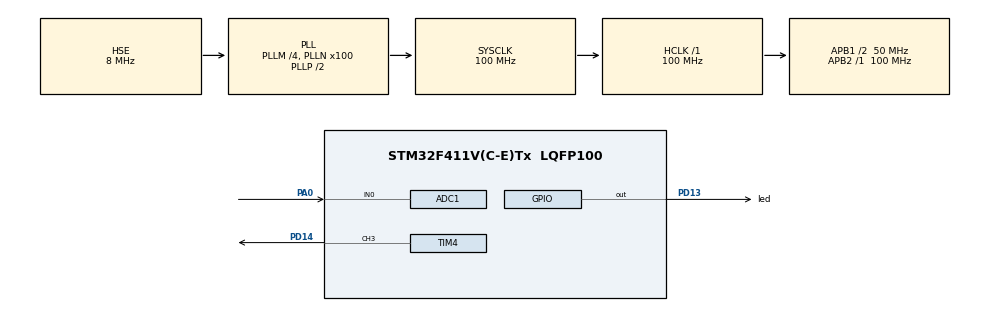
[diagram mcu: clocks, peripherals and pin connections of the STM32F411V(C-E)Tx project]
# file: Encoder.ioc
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ADC1.Channel-16\#ChannelRegularConversion=ADC_CHANNEL_0
ADC1.ClockPrescaler=ADC_CLOCK_SYNC_PCLK_DIV8
ADC1.ContinuousConvMode=ENABLE
ADC1.DMAContinuousRequests=ENABLE
ADC1.DataAlign=ADC_DATAALIGN_RIGHT
ADC1.DiscontinuousConvMode=DISABLE
ADC1.EOCSelection=ADC_EOC_SINGLE_CONV
ADC1.EnableAnalogWatchDog=false
ADC1.ExternalTrigConv=ADC_SOFTWARE_START
ADC1.ExternalTrigConvEdge=ADC_EXTERNALTRIGCONVEDGE_NONE
ADC1.InjNumberOfConversion=0
ADC1.NbrOfConversion=1
ADC1.NbrOfConversionFlag=1
ADC1.Rank-16\#ChannelRegularConversion=1
ADC1.Resolution=ADC_RESOLUTION_12B
ADC1.SamplingTime-16\#ChannelRegularConversion=ADC_SAMPLETIME_480CYCLES
ADC1.ScanConvMode=ENABLE
ADC1.master=1
Dma.ADC1.0.Direction=DMA_PERIPH_TO_MEMORY
Dma.ADC1.0.FIFOMode=DMA_FIFOMODE_DISABLE
Dma.ADC1.0.Instance=DMA2_Stream0
Dma.ADC1.0.MemDataAlignment=DMA_MDATAALIGN_HALFWORD
Dma.ADC1.0.MemInc=DMA_MINC_ENABLE
Dma.ADC1.0.Mode=DMA_CIRCULAR
Dma.ADC1.0.PeriphDataAlignment=DMA_PDATAALIGN_HALFWORD
Dma.ADC1.0.PeriphInc=DMA_PINC_DISABLE
Dma.ADC1.0.Priority=DMA_PRIORITY_LOW
Dma.Request0=ADC1
Dma.Request1=TIM4_CH3
Dma.TIM4_CH3.1.Direction=DMA_PERIPH_TO_MEMORY
Dma.TIM4_CH3.1.FIFOMode=DMA_FIFOMODE_DISABLE
Dma.TIM4_CH3.1.Instance=DMA1_Stream7
Dma.TIM4_CH3.1.MemDataAlignment=DMA_MDATAALIGN_HALFWORD
Dma.TIM4_CH3.1.MemInc=DMA_MINC_ENABLE
Dma.TIM4_CH3.1.Mode=DMA_CIRCULAR
Dma.TIM4_CH3.1.PeriphDataAlignment=DMA_PDATAALIGN_HALFWORD
Dma.TIM4_CH3.1.PeriphInc=DMA_PINC_DISABLE
Dma.TIM4_CH3.1.Priority=DMA_PRIORITY_LOW
Mcu.Family=STM32F4
Mcu.Name=STM32F411V(C-E)Tx
Mcu.Package=LQFP100
NVIC.DMA1_Stream7_IRQn=true\:0\:0\:false\:false\:true
NVIC.DMA2_Stream0_IRQn=true\:0\:0\:false\:false\:true
NVIC.PriorityGroup=NVIC_PRIORITYGROUP_4
PA0-WKUP.Signal=ADCx_IN0
PD13.GPIO_Label=led
PD13.Signal=GPIO_Output
PD14.Signal=S_TIM4_CH3
PH0\ -\ OSC_IN.Mode=HSE-External-Oscillator
PH0\ -\ OSC_IN.Signal=RCC_OSC_IN
PH1\ -\ OSC_OUT.Mode=HSE-External-Oscillator
PH1\ -\ OSC_OUT.Signal=RCC_OSC_OUT
ProjectManager.HeapSize=0x200
ProjectManager.StackSize=0x400
ProjectManager.TargetToolchain=SW4STM32
RCC.48MHZClocksFreq_Value=50000000
RCC.AHBFreq_Value=100000000
RCC.APB1CLKDivider=RCC_HCLK_DIV2
RCC.APB1Freq_Value=50000000
RCC.APB1TimFreq_Value=100000000
RCC.APB2Freq_Value=100000000
RCC.APB2TimFreq_Value=100000000
RCC.CortexFreq_Value=100000000
RCC.HCLKFreq_Value=100000000
RCC.HSE_VALUE=8000000
RCC.HSI_VALUE=16000000
RCC.LSE_VALUE=32768
RCC.PLLM=4
RCC.PLLN=100
RCC.PLLSourceVirtual=RCC_PLLSOURCE_HSE
RCC.SYSCLKFreq_VALUE=100000000
RCC.SYSCLKSource=RCC_SYSCLKSOURCE_PLLCLK
RCC.VCOOutputFreq_Value=200000000
SH.ADCx_IN0.0=ADC1_IN0,IN0
SH.S_TIM4_CH3.0=TIM4_CH3,PWM Generation3 CH3
TIM4.Channel-PWM\ Generation3\ CH3=TIM_CHANNEL_3
TIM4.Period=99
TIM4.Prescaler=4999
VP_TIM4_VS_ClockSourceINT.Mode=Internal
board=Encoder

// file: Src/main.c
/**
  ******************************************************************************
  * File Name          : main.c
  * Description        : Main program body
  ******************************************************************************
  *
  * COPYRIGHT(c) 2017 STMicroelectronics
  *
  * Redistribution and use in source and binary forms, with or without modification,
  * are permitted provided that the following conditions are met:
  *   1. Redistributions of source code must retain the above copyright notice,
  *      this list of conditions and the following disclaimer.
  *   2. Redistributions in binary form must reproduce the above copyright notice,
  *      this list of conditions and the following disclaimer in the documentation
  *      and/or other materials provided with the distribution.
  *   3. Neither the name of STMicroelectronics nor the names of its contributors
  *      may be used to endorse or promote products derived from this software
  *      without specific prior written permission.
  *
  * THIS SOFTWARE IS PROVIDED BY THE COPYRIGHT HOLDERS AND CONTRIBUTORS "AS IS"
  * AND ANY EXPRESS OR IMPLIED WARRANTIES, INCLUDING, BUT NOT LIMITED TO, THE
  * IMPLIED WARRANTIES OF MERCHANTABILITY AND FITNESS FOR A PARTICULAR PURPOSE ARE
  * DISCLAIMED. IN NO EVENT SHALL THE COPYRIGHT HOLDER OR CONTRIBUTORS BE LIABLE
  * FOR ANY DIRECT, INDIRECT, INCIDENTAL, SPECIAL, EXEMPLARY, OR CONSEQUENTIAL
  * DAMAGES (INCLUDING, BUT NOT LIMITED TO, PROCUREMENT OF SUBSTITUTE GOODS OR
  * SERVICES; LOSS OF USE, DATA, OR PROFITS; OR BUSINESS INTERRUPTION) HOWEVER
  * CAUSED AND ON ANY THEORY OF LIABILITY, WHETHER IN CONTRACT, STRICT LIABILITY,
  * OR TORT (INCLUDING NEGLIGENCE OR OTHERWISE) ARISING IN ANY WAY OUT OF THE USE
  * OF THIS SOFTWARE, EVEN IF ADVISED OF THE POSSIBILITY OF SUCH DAMAGE.
  *
  ******************************************************************************
  */
#include "main.h"
#include "stm32f4xx_hal.h"

ADC_HandleTypeDef hadc1;
DMA_HandleTypeDef hdma_adc1;

TIM_HandleTypeDef htim4;
DMA_HandleTypeDef hdma_tim4_ch3;

/* USER CODE BEGIN PV */
/* Private variables ---------------------------------------------------------*/
uint16_t PomiarADC, temp;
float Temperature;
float Vsense;

const float V25 = 0.76; // [Volts]
const float Avg_slope = 0.0025; //[Volts/degree]
const float SupplyVoltage = 3.0; // [Volts]
const float ADCResolution = 4096.0;

uint8_t flag;
/* USER CODE END PV */

void SystemClock_Config(void);
void Error_Handler(void);
static void MX_GPIO_Init(void);
static void MX_DMA_Init(void);
static void MX_ADC1_Init(void);
static void MX_TIM4_Init(void);

void HAL_TIM_MspPostInit(TIM_HandleTypeDef *htim);

void HAL_SYSTICK_Callback(void) {
	temp = (PomiarADC*100)/(ADCResolution - 1);
	TIM4->CCR3 = temp;
}

/* USER CODE BEGIN PFP */
/* Private function prototypes -----------------------------------------------*/
//void HAL_ADC_ConvCpltCallback(ADC_HandleTypeDef* hadc) {
//	PomiarADC = HAL_ADC_GetValue(&hadc1); // Pobranie zmierzonej wartosci
//	Vsense = (SupplyVoltage * PomiarADC) / (ADCResolution - 1); // Przeliczenie wartosci zmierzonej na napiecie
//	Temperature = ((Vsense - V25) / Avg_slope) + 25; // Obliczenie temperatury
//}
/* USER CODE END PFP */

int main(void)
{

  /* MCU Configuration----------------------------------------------------------*/

  /* Reset of all peripherals, Initializes the Flash interface and the Systick. */
  HAL_Init();

  /* Configure the system clock */
  SystemClock_Config();

  /* Initialize all configured peripherals */
  MX_GPIO_Init();
  MX_DMA_Init();
  MX_ADC1_Init();
  MX_TIM4_Init();

  /* USER CODE BEGIN 2 */
	HAL_ADC_Start_DMA(&hadc1, (uint32_t*)&PomiarADC, 1);
	HAL_TIM_PWM_Start_DMA(&htim4, TIM_CHANNEL_3, (uint32_t*)&temp, 1);

  /* USER CODE END 2 */

  /* Infinite loop */
  /* USER CODE BEGIN WHILE */
	while (1) {
//		for (uint8_t i = 0; i < 100; i++) {
//			TIM4->CCR3 = i;
//			HAL_Delay(50);
//		}
//		HAL_Delay(100);
//		for (uint8_t i = 100; i > 0; i--) {
//			TIM4->CCR3 = i;
//			HAL_Delay(50);
//		}
  /* USER CODE END WHILE */

	}

}

/** System Clock Configuration
*/
void SystemClock_Config(void)
{

  RCC_OscInitTypeDef RCC_OscInitStruct;
  RCC_ClkInitTypeDef RCC_ClkInitStruct;

    /**Configure the main internal regulator output voltage
    */
  __HAL_RCC_PWR_CLK_ENABLE();

  __HAL_PWR_VOLTAGESCALING_CONFIG(PWR_REGULATOR_VOLTAGE_SCALE1);

    /**Initializes the CPU, AHB and APB busses clocks
    */
  RCC_OscInitStruct.OscillatorType = RCC_OSCILLATORTYPE_HSE;
  RCC_OscInitStruct.HSEState = RCC_HSE_ON;
  RCC_OscInitStruct.PLL.PLLState = RCC_PLL_ON;
  RCC_OscInitStruct.PLL.PLLSource = RCC_PLLSOURCE_HSE;
  RCC_OscInitStruct.PLL.PLLM = 4;
  RCC_OscInitStruct.PLL.PLLN = 100;
  RCC_OscInitStruct.PLL.PLLP = RCC_PLLP_DIV2;
  RCC_OscInitStruct.PLL.PLLQ = 4;
  if (HAL_RCC_OscConfig(&RCC_OscInitStruct) != HAL_OK)
  {
    Error_Handler();
  }

    /**Initializes the CPU, AHB and APB busses clocks
    */
  RCC_ClkInitStruct.ClockType = RCC_CLOCKTYPE_HCLK|RCC_CLOCKTYPE_SYSCLK
                              |RCC_CLOCKTYPE_PCLK1|RCC_CLOCKTYPE_PCLK2;
  RCC_ClkInitStruct.SYSCLKSource = RCC_SYSCLKSOURCE_PLLCLK;
  RCC_ClkInitStruct.AHBCLKDivider = RCC_SYSCLK_DIV1;
  RCC_ClkInitStruct.APB1CLKDivider = RCC_HCLK_DIV2;
  RCC_ClkInitStruct.APB2CLKDivider = RCC_HCLK_DIV1;

  if (HAL_RCC_ClockConfig(&RCC_ClkInitStruct, FLASH_LATENCY_3) != HAL_OK)
  {
    Error_Handler();
  }

    /**Configure the Systick interrupt time
    */
  HAL_SYSTICK_Config(HAL_RCC_GetHCLKFreq()/1000);

    /**Configure the Systick
    */
  HAL_SYSTICK_CLKSourceConfig(SYSTICK_CLKSOURCE_HCLK);

  /* SysTick_IRQn interrupt configuration */
  HAL_NVIC_SetPriority(SysTick_IRQn, 0, 0);
}

/* ADC1 init function */
static void MX_ADC1_Init(void)
{

  ADC_ChannelConfTypeDef sConfig;

    /**Configure the global features of the ADC (Clock, Resolution, Data Alignment and number of conversion)
    */
  hadc1.Instance = ADC1;
  hadc1.Init.ClockPrescaler = ADC_CLOCK_SYNC_PCLK_DIV8;
  hadc1.Init.Resolution = ADC_RESOLUTION_12B;
  hadc1.Init.ScanConvMode = ENABLE;
  hadc1.Init.ContinuousConvMode = ENABLE;
  hadc1.Init.DiscontinuousConvMode = DISABLE;
  hadc1.Init.ExternalTrigConvEdge = ADC_EXTERNALTRIGCONVEDGE_NONE;
  hadc1.Init.ExternalTrigConv = ADC_SOFTWARE_START;
  hadc1.Init.DataAlign = ADC_DATAALIGN_RIGHT;
  hadc1.Init.NbrOfConversion = 1;
  hadc1.Init.DMAContinuousRequests = ENABLE;
  hadc1.Init.EOCSelection = ADC_EOC_SINGLE_CONV;
  if (HAL_ADC_Init(&hadc1) != HAL_OK)
  {
    Error_Handler();
  }

    /**Configure for the selected ADC regular channel its corresponding rank in the sequencer and its sample time.
    */
  sConfig.Channel = ADC_CHANNEL_0;
  sConfig.Rank = 1;
  sConfig.SamplingTime = ADC_SAMPLETIME_480CYCLES;
  if (HAL_ADC_ConfigChannel(&hadc1, &sConfig) != HAL_OK)
  {
    Error_Handler();
  }

}

/* TIM4 init function */
static void MX_TIM4_Init(void)
{

  TIM_ClockConfigTypeDef sClockSourceConfig;
  TIM_MasterConfigTypeDef sMasterConfig;
  TIM_OC_InitTypeDef sConfigOC;

  htim4.Instance = TIM4;
  htim4.Init.Prescaler = 4999;
  htim4.Init.CounterMode = TIM_COUNTERMODE_UP;
  htim4.Init.Period = 99;
  htim4.Init.ClockDivision = TIM_CLOCKDIVISION_DIV1;
  if (HAL_TIM_Base_Init(&htim4) != HAL_OK)
  {
    Error_Handler();
  }

  sClockSourceConfig.ClockSource = TIM_CLOCKSOURCE_INTERNAL;
  if (HAL_TIM_ConfigClockSource(&htim4, &sClockSourceConfig) != HAL_OK)
  {
    Error_Handler();
  }

  if (HAL_TIM_PWM_Init(&htim4) != HAL_OK)
  {
    Error_Handler();
  }

  sMasterConfig.MasterOutputTrigger = TIM_TRGO_RESET;
  sMasterConfig.MasterSlaveMode = TIM_MASTERSLAVEMODE_DISABLE;
  if (HAL_TIMEx_MasterConfigSynchronization(&htim4, &sMasterConfig) != HAL_OK)
  {
    Error_Handler();
  }

  sConfigOC.OCMode = TIM_OCMODE_PWM1;
  sConfigOC.Pulse = 0;
  sConfigOC.OCPolarity = TIM_OCPOLARITY_HIGH;
  sConfigOC.OCFastMode = TIM_OCFAST_DISABLE;
  if (HAL_TIM_PWM_ConfigChannel(&htim4, &sConfigOC, TIM_CHANNEL_3) != HAL_OK)
  {
    Error_Handler();
  }

  HAL_TIM_MspPostInit(&htim4);

}

static void MX_DMA_Init(void)
{
  /* DMA controller clock enable */
  __HAL_RCC_DMA2_CLK_ENABLE();
  __HAL_RCC_DMA1_CLK_ENABLE();

  /* DMA interrupt init */
  /* DMA1_Stream7_IRQn interrupt configuration */
  HAL_NVIC_SetPriority(DMA1_Stream7_IRQn, 0, 0);
  HAL_NVIC_EnableIRQ(DMA1_Stream7_IRQn);
  /* DMA2_Stream0_IRQn interrupt configuration */
  HAL_NVIC_SetPriority(DMA2_Stream0_IRQn, 0, 0);
  HAL_NVIC_EnableIRQ(DMA2_Stream0_IRQn);

}

/** Configure pins as
        * Analog
        * Input
        * Output
        * EVENT_OUT
        * EXTI
*/
static void MX_GPIO_Init(void)
{

  GPIO_InitTypeDef GPIO_InitStruct;

  /* GPIO Ports Clock Enable */
  __HAL_RCC_GPIOH_CLK_ENABLE();
  __HAL_RCC_GPIOA_CLK_ENABLE();
  __HAL_RCC_GPIOD_CLK_ENABLE();

  /*Configure GPIO pin Output Level */
  HAL_GPIO_WritePin(led_GPIO_Port, led_Pin, GPIO_PIN_RESET);

  /*Configure GPIO pin : led_Pin */
  GPIO_InitStruct.Pin = led_Pin;
  GPIO_InitStruct.Mode = GPIO_MODE_OUTPUT_PP;
  GPIO_InitStruct.Pull = GPIO_NOPULL;
  GPIO_InitStruct.Speed = GPIO_SPEED_FREQ_LOW;
  HAL_GPIO_Init(led_GPIO_Port, &GPIO_InitStruct);

}

void Error_Handler(void)
{
	while (1) {
	}
}

/************************ (C) COPYRIGHT STMicroelectronics *****END OF FILE****/
